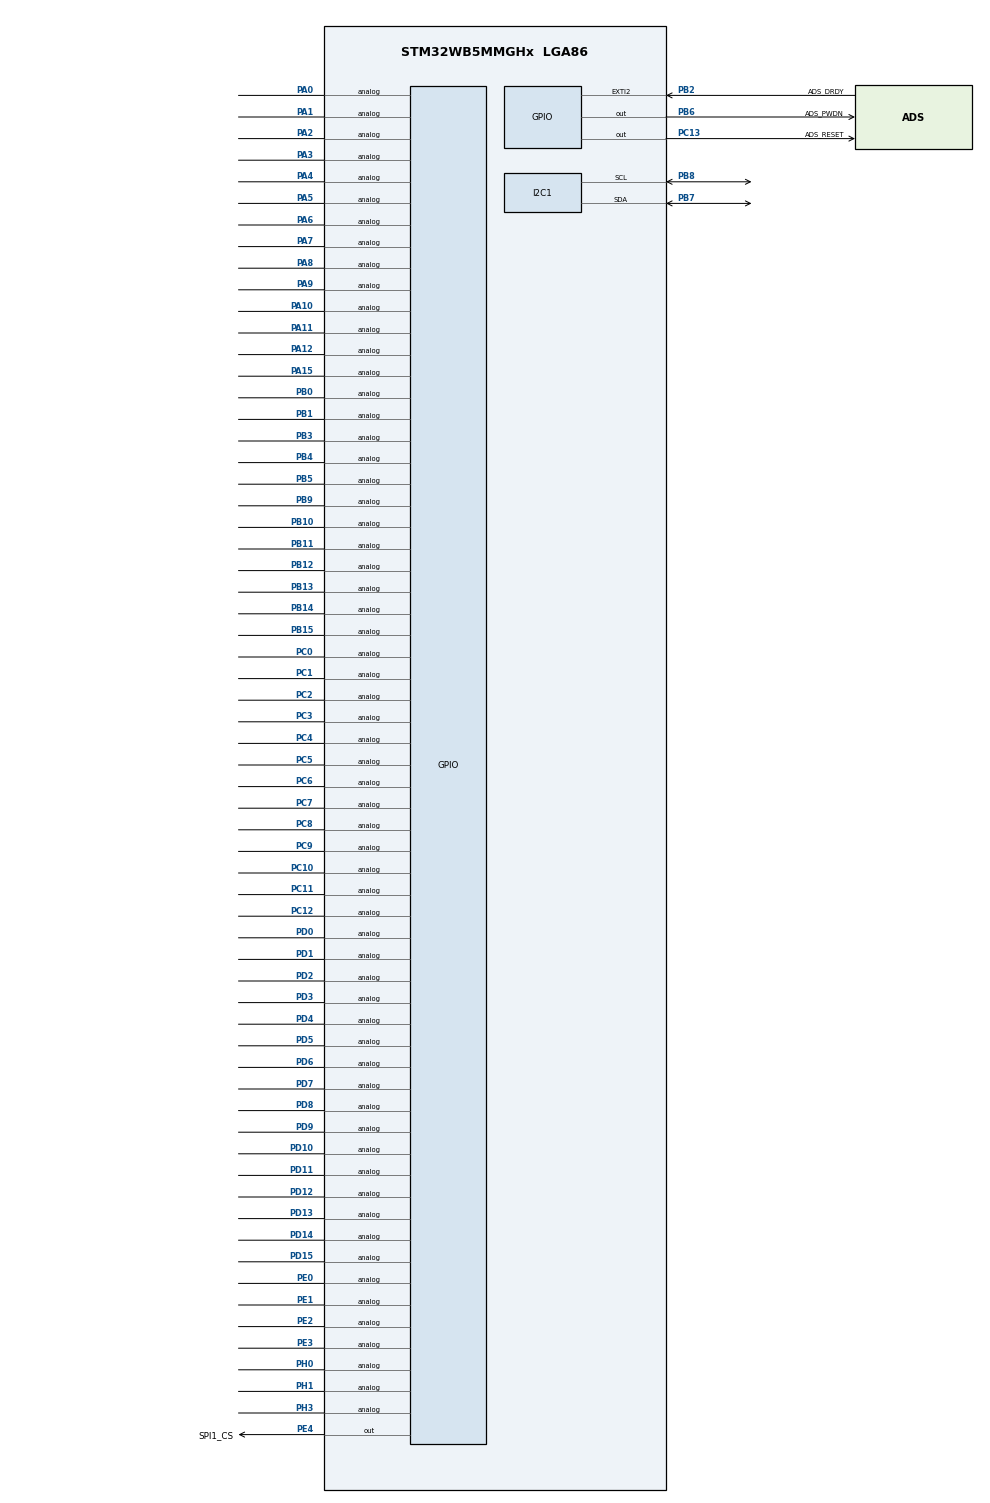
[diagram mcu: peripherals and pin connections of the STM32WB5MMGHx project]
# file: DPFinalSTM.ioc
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ANT_IN.Signal=GPIO_Analog
ANT_NC.Signal=GPIO_Analog
I2C1.Timing=0x00201D2B
Mcu.Family=STM32WB
Mcu.Name=STM32WB5MMGHx
Mcu.Package=LGA86
NVIC.EXTI2_IRQn=true\:0\:0\:false\:false\:true\:true\:true\:true
NVIC.HSEM_IRQn=true\:0\:0\:false\:false\:true\:false\:true\:true
NVIC.IPCC_C1_RX_IRQn=true\:0\:0\:false\:false\:true\:true\:true\:true
NVIC.IPCC_C1_TX_IRQn=true\:0\:0\:false\:false\:true\:true\:true\:true
NVIC.PriorityGroup=NVIC_PRIORITYGROUP_4
NVIC.RCC_IRQn=true\:0\:0\:false\:false\:true\:true\:false\:true
NVIC.RTC_WKUP_IRQn=true\:0\:0\:false\:false\:true\:true\:true\:true
PA0.Signal=GPIO_Analog
PA1.Signal=GPIO_Analog
PA10.Signal=GPIO_Analog
PA11.Signal=GPIO_Analog
PA12.Signal=GPIO_Analog
PA13.Mode=Serial_Wire
PA13.Signal=SYS_JTMS-SWDIO
PA14.Mode=Serial_Wire
PA14.Signal=SYS_JTCK-SWCLK
PA15.Signal=GPIO_Analog
PA2.Signal=GPIO_Analog
PA3.Signal=GPIO_Analog
PA4.Signal=GPIO_Analog
PA5.Signal=GPIO_Analog
PA6.Signal=GPIO_Analog
PA7.Signal=GPIO_Analog
PA8.Signal=GPIO_Analog
PA9.Signal=GPIO_Analog
PB0.Signal=GPIO_Analog
PB1.Signal=GPIO_Analog
PB10.Signal=GPIO_Analog
PB11.Signal=GPIO_Analog
PB12.Signal=GPIO_Analog
PB13.Signal=GPIO_Analog
PB14.Signal=GPIO_Analog
PB15.Signal=GPIO_Analog
PB2.GPIO_Label=ADS_DRDY
PB2.GPIO_ModeDefaultEXTI=GPIO_MODE_IT_FALLING
PB2.GPIO_PuPd=GPIO_PULLUP
PB2.Signal=GPXTI2
PB3.Signal=GPIO_Analog
PB4.Signal=GPIO_Analog
PB5.Signal=GPIO_Analog
PB6.GPIO_Label=ADS_PWDN
PB6.Signal=GPIO_Output
PB7.GPIO_Pu=GPIO_PULLUP
PB7.Mode=I2C
PB7.Signal=I2C1_SDA
PB8.GPIO_Pu=GPIO_PULLUP
PB8.Mode=I2C
PB8.Signal=I2C1_SCL
PB9.Signal=GPIO_Analog
PC0.Signal=GPIO_Analog
PC1.Signal=GPIO_Analog
PC10.Signal=GPIO_Analog
PC11.Signal=GPIO_Analog
PC12.Signal=GPIO_Analog
PC13.GPIO_Label=ADS_RESET
PC13.Signal=GPIO_Output
PC2.Signal=GPIO_Analog
PC3.Signal=GPIO_Analog
PC4.Signal=GPIO_Analog
PC5.Signal=GPIO_Analog
PC6.Signal=GPIO_Analog
PC7.Signal=GPIO_Analog
PC8.Signal=GPIO_Analog
PC9.Signal=GPIO_Analog
PD0.Signal=GPIO_Analog
PD1.Signal=GPIO_Analog
PD10.Signal=GPIO_Analog
PD11.Signal=GPIO_Analog
PD12.Signal=GPIO_Analog
PD13.Signal=GPIO_Analog
PD14.Signal=GPIO_Analog
PD15.Signal=GPIO_Analog
PD2.Signal=GPIO_Analog
PD3.Signal=GPIO_Analog
PD4.Signal=GPIO_Analog
PD5.Signal=GPIO_Analog
PD6.Signal=GPIO_Analog
PD7.Signal=GPIO_Analog
PD8.Signal=GPIO_Analog
PD9.Signal=GPIO_Analog
PE0.Signal=GPIO_Analog
PE1.Signal=GPIO_Analog
PE2.Signal=GPIO_Analog
PE3.Signal=GPIO_Analog
PE4.GPIO_Label=SPI1_CS
PE4.Signal=GPIO_Output
PH0.Signal=GPIO_Analog
PH1.Signal=GPIO_Analog
PH3-BOOT0.Signal=GPIO_Analog
ProjectManager.HeapSize=0x200
ProjectManager.StackSize=0x400
ProjectManager.TargetToolchain=STM32CubeIDE
RCC.AHBCLKDivider=RCC_SYSCLK_DIV4
RCC.AHBFreq_Value=8000000
RCC.APB1Freq_Value=8000000
RCC.APB1TimFreq_Value=8000000
RCC.APB2Freq_Value=8000000
RCC.APB2TimFreq_Value=8000000
RCC.APB3Freq_Value=16000000
RCC.CortexFreq_Value=8000000
RCC.HCLKFreq_Value=8000000
RCC.HSE_VALUE=32000000
RCC.HSI48_VALUE=48000000
RCC.HSI_VALUE=16000000
RCC.PLLN=32
RCC.PLLR=RCC_PLLR_DIV4
RCC.SYSCLKFreq_VALUE=32000000
RCC.SYSCLKSource=RCC_SYSCLKSOURCE_PLLCLK
RCC.VCOOutputFreq_Value=128000000
RF_OUT.Signal=GPIO_Analog
STM32_WPAN.AD_TYPE_COMPLETE_LOCAL_NAME=BalodiHeart
STM32_WPAN.AD_TYPE_COMPLETE_LOCAL_NAME_LENGTH=12
STM32_WPAN.BLE_CFG_CLT_MAX_NBR_CB=5
STM32_WPAN.CFG_BLE_ATT_VALUE_ARRAY_SIZE=6000
STM32_WPAN.CFG_BLE_MAX_ATT_MTU=500
STM32_WPAN.CFG_HW_TS_MAX_NBR_CONCURRENT_TIMER=10
STM32_WPAN.CFG_HW_TS_NVIC_RTC_WAKEUP_IT_PREEMPTPRIO=0
STM32_WPAN.CFG_LPM_SUPPORTED=0
STM32_WPAN.CFG_LSCLK_LSE=0
STM32_WPAN.CFG_USE_SMPS=1
STM32_WPAN.CUSTOM_P2P_SERVER=Disabled
STM32_WPAN.CUSTOM_TEMPLATE=Enabled
STM32_WPAN.INCLUDE_AD_TYPE_COMPLETE_LOCAL_NAME=1
STM32_WPAN.INCLUDE_AD_TYPE_MANUFACTURER_SPECIFIC_DATA=1
STM32_WPAN.INCLUDE_AD_TYPE_TX_POWER_LEVEL=1
STM32_WPAN.LOCAL_NAME=BalodiK
STM32_WPAN.LOCAL_NAME_FORMATTED=,'B','a','l','o','d','i','K'
STM32_WPAN.NUMBER_OF_SERVICES=1
STM32_WPAN.PAIRING_PARAMETERS=OFF
STM32_WPAN.SERVICE1_CHAR1_LONG_NAME=BalodiHeartWave
STM32_WPAN.SERVICE1_CHAR1_PROP_INDICATE=CHAR_PROP_INDICATE
STM32_WPAN.SERVICE1_CHAR1_PROP_NOTIFY=CHAR_PROP_NOTIFY
STM32_WPAN.SERVICE1_CHAR1_PROP_READ=CHAR_PROP_READ
STM32_WPAN.SERVICE1_CHAR1_PROP_WRITE=CHAR_PROP_WRITE
STM32_WPAN.SERVICE1_CHAR1_PROP_WRITE_WITHOUT_RESP=CHAR_PROP_WRITE_WITHOUT_RESP
STM32_WPAN.SERVICE1_CHAR1_SHORT_NAME=BHW
STM32_WPAN.SERVICE1_CHAR1_UUID=00 10
STM32_WPAN.SERVICE1_CHAR1_UUID_TYPE=0x01
STM32_WPAN.SERVICE1_CHAR1_VALUE_LENGTH=300
STM32_WPAN.SERVICE1_CHAR2_LONG_NAME=BalodiHeartRate
STM32_WPAN.SERVICE1_CHAR2_PROP_INDICATE=CHAR_PROP_INDICATE
STM32_WPAN.SERVICE1_CHAR2_PROP_NOTIFY=CHAR_PROP_NOTIFY
STM32_WPAN.SERVICE1_CHAR2_PROP_READ=CHAR_PROP_READ
STM32_WPAN.SERVICE1_CHAR2_PROP_WRITE=CHAR_PROP_WRITE
STM32_WPAN.SERVICE1_CHAR2_PROP_WRITE_WITHOUT_RESP=CHAR_PROP_WRITE_WITHOUT_RESP
STM32_WPAN.SERVICE1_CHAR2_SHORT_NAME=BHR
STM32_WPAN.SERVICE1_CHAR2_UUID=00 01
STM32_WPAN.SERVICE1_CHAR3_LONG_NAME=BalodiHRV
STM32_WPAN.SERVICE1_CHAR3_PROP_INDICATE=CHAR_PROP_INDICATE
STM32_WPAN.SERVICE1_CHAR3_PROP_NOTIFY=CHAR_PROP_NOTIFY
STM32_WPAN.SERVICE1_CHAR3_PROP_READ=CHAR_PROP_READ
STM32_WPAN.SERVICE1_CHAR3_PROP_WRITE=CHAR_PROP_WRITE
STM32_WPAN.SERVICE1_CHAR3_PROP_WRITE_WITHOUT_RESP=CHAR_PROP_WRITE_WITHOUT_RESP
STM32_WPAN.SERVICE1_CHAR3_SHORT_NAME=BHRV
STM32_WPAN.SERVICE1_CHAR3_UUID=00 02
STM32_WPAN.SERVICE1_CHAR3_VALUE_LENGTH=50
STM32_WPAN.SERVICE1_LONG_NAME=BalodiHeart
STM32_WPAN.SERVICE1_NUMBER_OF_CHARACTERISTICS=3
STM32_WPAN.SERVICE1_SHORT_NAME=BH
STM32_WPAN.SERVICE1_UUID=00 01
STM32_WPAN.SERVICE1_UUID_TYPE=0x01
VP_HSEM_VS_HSEM.Mode=HSEM_Activate
VP_IPCC_VS_IPCC.Mode=IPCC_Activate
VP_MEMORYMAP_VS_MEMORYMAP.Mode=CurAppReg
VP_RCC_V_OSC32_IN.Mode=LSE-External-Clock-Source
VP_RCC_V_OSC_IN.Mode=HSE-External-Clock-Source
VP_RF_VS_RF.Mode=RF_Activate
VP_RTC_VS_RTC_Activate.Mode=RTC_Enabled
VP_RTC_VS_RTC_WakeUp_intern.Mode=WakeUp
VP_SEQUENCER_VS_SEQUENCER.Mode=SEQUENCER_Enabled
VP_STM32_WPAN_VS_BLE_HOST.Mode=STM32_WPAN_Enabled
VP_TINY_LPM_VS_TINY_LPM.Mode=TINY_LPM_Enabled
board=custom

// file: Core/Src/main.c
/* USER CODE BEGIN Header */
/**
  ******************************************************************************
  * @file           : main.c
  * @brief          : Main program body
  ******************************************************************************
  * @attention
  *
  * Copyright (c) 2025 STMicroelectronics.
  * All rights reserved.
  *
  * This software is licensed under terms that can be found in the LICENSE file
  * in the root directory of this software component.
  * If no LICENSE file comes with this software, it is provided AS-IS.
  *
  ******************************************************************************
  */
/* USER CODE END Header */
#include "main.h"
#include "i2c.h"
#include "ipcc.h"
#include "memorymap.h"
#include "rf.h"
#include "rtc.h"
#include "gpio.h"

/* USER CODE BEGIN Includes */
#include "ADPD1080.h"
#include "ADP1080_REG_GEN.h"
#include "custom_app.h"
//#include "LSM6DSLTR.h"
#include "stm32_lpm.h"
#include "LSM6DSL.h"

/* USER CODE END Includes */

/* USER CODE BEGIN PTD */
#define LSM6DSL_ADDR 0x6A  // or 0x6B depending on SA0

// Registers
#define WHO_AM_I          0x0F
#define CTRL1_XL         0x10
#define CTRL10_C         0x19
#define TAP_CFG          0x58
#define STEP_COUNTER_L   0x4B
#define STEP_COUNTER_H   0x4C

#define STTS22H_I2C_ADDR 0x3F  // if SA0 = GND
#define STTS22H_CTRL_REG        0x04  // Control register
#define STTS22H_TEMP_L_OUT_REG  0x06  // Temperature LSB
#define STTS22H_TEMP_H_OUT_REG  0x07  // Temperature MSB

// Register addresses

#define TEMP_L_REG   0x06
#define TEMP_H_REG   0x07

/* USER CODE END PTD */

/* USER CODE BEGIN PD */
#define ADPD1080_REG_ADDR      0x14        // Register address to write
#define VALUE_TO_WRITE         0x0557      // 16-bit value to write

/* USER CODE END PD */

/* USER CODE BEGIN PV */

HAL_I2C_StateTypeDef state;
HAL_StatusTypeDef i2cStatus;
volatile int32_t count=0;
uint8_t reg_data[2];
volatile uint16_t read_value = 0;
uint8_t register_value2[2] ;
uint8_t accel_data[6];
uint8_t check=0;
uint8_t data[2];
float temperature;

/* USER CODE END PV */

void SystemClock_Config(void);
void PeriphCommonClock_Config(void);
/* USER CODE BEGIN PFP */
void Custom( void );

/* USER CODE END PFP */

/* USER CODE BEGIN 0 */
uint8_t temp_l, temp_h;
    int16_t raw_temp;
/* USER CODE END 0 */

int main(void)
{

  /* MCU Configuration--------------------------------------------------------*/

  /* Reset of all peripherals, Initializes the Flash interface and the Systick. */
  HAL_Init();
  /* Config code for STM32_WPAN (HSE Tuning must be done before system clock configuration) */
  MX_APPE_Config();

  /* Configure the system clock */
  SystemClock_Config();

  /* Configure the peripherals common clocks */
  PeriphCommonClock_Config();

  /* IPCC initialisation */
  MX_IPCC_Init();

  /* Initialize all configured peripherals */
  MX_RF_Init();
  MX_GPIO_Init();
  MX_RTC_Init();
  MX_I2C1_Init();
  /* USER CODE BEGIN 2 */
  //LSM6DSL_Init();

  uint8_t data1;
  ADPD1080_ReadAllRegisters(&hi2c1);
  ADPD1080_CheckRegisters(&hi2c1);
  HAL_I2C_Mem_Read(&hi2c1, ADPD1080_ADDR, 0x14, I2C_MEMADD_SIZE_8BIT, reg_data, 2, HAL_MAX_DELAY);
  //HAL_I2C_Mem_Read(&hi2c1, LSM6DSL_ADDR, 0x11, I2C_MEMADD_SIZE_8BIT, register_value2, 2, HAL_MAX_DELAY);
  // 1. Configure accelerometer (416Hz, ±8g) - do this once at startup
   // 4. Add small delay between readings
  HAL_Delay(100);

     // Initialize ADS1296 properly

    ADPD1080_LEDoff(&hi2c1);

    data1 = 0xAA;  // 0b10101010 = enabled, 25Hz, BDU
       HAL_I2C_Mem_Write(&hi2c1, STTS22H_I2C_ADDR << 1, STTS22H_CTRL_REG,
                                I2C_MEMADD_SIZE_8BIT, &data1, 1, HAL_MAX_DELAY);

  /* USER CODE END 2 */

  /* Init code for STM32_WPAN */
  MX_APPE_Init();

  /* Infinite loop */
  while (1)
  {
    MX_APPE_Process();

    /* USER CODE BEGIN 3 */
	  //HAL_I2C_Mem_Read(&hi2c1, 0x6A<<1, 0x0F, I2C_MEMADD_SIZE_8BIT, &check, 1, HAL_MAX_DELAY);
	  count++;
	  // Read TEMP_L

	  //HAL_I2C_Mem_Read(&hi2c1, 0xD4, 0x28, I2C_MEMADD_SIZE_8BIT, accel_data, 6, HAL_MAX_DELAY);

  }
  /* USER CODE END 3 */
}

void SystemClock_Config(void)
{
  RCC_OscInitTypeDef RCC_OscInitStruct = {0};
  RCC_ClkInitTypeDef RCC_ClkInitStruct = {0};

  /** Configure the main internal regulator output voltage
  */
  __HAL_PWR_VOLTAGESCALING_CONFIG(PWR_REGULATOR_VOLTAGE_SCALE1);

  /** Initializes the RCC Oscillators according to the specified parameters
  * in the RCC_OscInitTypeDef structure.
  */
  RCC_OscInitStruct.OscillatorType = RCC_OSCILLATORTYPE_HSI|RCC_OSCILLATORTYPE_LSI1
                              |RCC_OSCILLATORTYPE_HSE|RCC_OSCILLATORTYPE_MSI;
  RCC_OscInitStruct.HSEState = RCC_HSE_ON;
  RCC_OscInitStruct.HSIState = RCC_HSI_ON;
  RCC_OscInitStruct.MSIState = RCC_MSI_ON;
  RCC_OscInitStruct.HSICalibrationValue = RCC_HSICALIBRATION_DEFAULT;
  RCC_OscInitStruct.MSICalibrationValue = RCC_MSICALIBRATION_DEFAULT;
  RCC_OscInitStruct.MSIClockRange = RCC_MSIRANGE_6;
  RCC_OscInitStruct.LSIState = RCC_LSI_ON;
  RCC_OscInitStruct.PLL.PLLState = RCC_PLL_ON;
  RCC_OscInitStruct.PLL.PLLSource = RCC_PLLSOURCE_MSI;
  RCC_OscInitStruct.PLL.PLLM = RCC_PLLM_DIV1;
  RCC_OscInitStruct.PLL.PLLN = 32;
  RCC_OscInitStruct.PLL.PLLP = RCC_PLLP_DIV2;
  RCC_OscInitStruct.PLL.PLLR = RCC_PLLR_DIV4;
  RCC_OscInitStruct.PLL.PLLQ = RCC_PLLQ_DIV2;
  if (HAL_RCC_OscConfig(&RCC_OscInitStruct) != HAL_OK)
  {
    Error_Handler();
  }

  /** Configure the SYSCLKSource, HCLK, PCLK1 and PCLK2 clocks dividers
  */
  RCC_ClkInitStruct.ClockType = RCC_CLOCKTYPE_HCLK4|RCC_CLOCKTYPE_HCLK2
                              |RCC_CLOCKTYPE_HCLK|RCC_CLOCKTYPE_SYSCLK
                              |RCC_CLOCKTYPE_PCLK1|RCC_CLOCKTYPE_PCLK2;
  RCC_ClkInitStruct.SYSCLKSource = RCC_SYSCLKSOURCE_PLLCLK;
  RCC_ClkInitStruct.AHBCLKDivider = RCC_SYSCLK_DIV4;
  RCC_ClkInitStruct.APB1CLKDivider = RCC_HCLK_DIV1;
  RCC_ClkInitStruct.APB2CLKDivider = RCC_HCLK_DIV1;
  RCC_ClkInitStruct.AHBCLK2Divider = RCC_SYSCLK_DIV1;
  RCC_ClkInitStruct.AHBCLK4Divider = RCC_SYSCLK_DIV1;

  if (HAL_RCC_ClockConfig(&RCC_ClkInitStruct, FLASH_LATENCY_1) != HAL_OK)
  {
    Error_Handler();
  }
}

void PeriphCommonClock_Config(void)
{
  RCC_PeriphCLKInitTypeDef PeriphClkInitStruct = {0};

  /** Initializes the peripherals clock
  */
  PeriphClkInitStruct.PeriphClockSelection = RCC_PERIPHCLK_SMPS|RCC_PERIPHCLK_RFWAKEUP;
  PeriphClkInitStruct.RFWakeUpClockSelection = RCC_RFWKPCLKSOURCE_HSE_DIV1024;
  PeriphClkInitStruct.SmpsClockSelection = RCC_SMPSCLKSOURCE_HSI;
  PeriphClkInitStruct.SmpsDivSelection = RCC_SMPSCLKDIV_RANGE1;

  if (HAL_RCCEx_PeriphCLKConfig(&PeriphClkInitStruct) != HAL_OK)
  {
    Error_Handler();
  }
}

void Error_Handler(void)
{
  __disable_irq();
  while (1)
  {
  }
}
